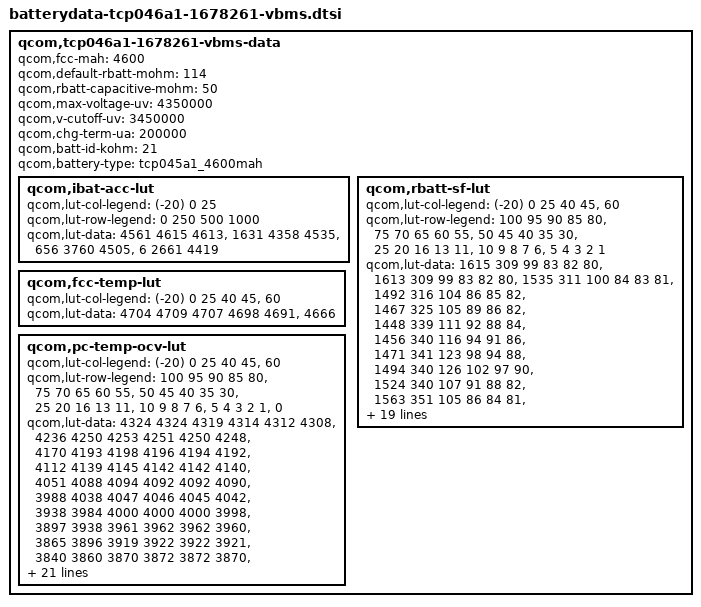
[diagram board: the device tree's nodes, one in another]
 qcom,tcp046a1-1678261-vbms-data {
	qcom,fcc-mah = <4600>;
	qcom,default-rbatt-mohm = <114>;
	qcom,rbatt-capacitive-mohm = <50>;
	qcom,max-voltage-uv = <4350000>;
	qcom,v-cutoff-uv = <3450000>;
	qcom,chg-term-ua = <200000>;
	qcom,batt-id-kohm = <21>;
	qcom,battery-type = "tcp045a1_4600mah";

	qcom,ibat-acc-lut {
		qcom,lut-col-legend = <(-20) 0 25>;
		qcom,lut-row-legend = <0 250 500 1000>;
		qcom,lut-data = <4561 4615 4613>,
				<1631 4358 4535>,
				<656 3760 4505>,
				<6 2661 4419>;
	};

	qcom,rbatt-sf-lut {
		qcom,lut-col-legend = <(-20) 0 25 40 45>,
				<60>;
		qcom,lut-row-legend = <100 95 90 85 80>,
				<75 70 65 60 55>,
				<50 45 40 35 30>,
				<25 20 16 13 11>,
				<10 9 8 7 6>,
				<5 4 3 2 1>;
		qcom,lut-data = <1615 309 99 83 82 80>,
				<1613 309 99 83 82 80>,
				<1535 311 100 84 83 81>,
				<1492 316 104 86 85 82>,
				<1467 325 105 89 86 82>,
				<1448 339 111 92 88 84>,
				<1456 340 116 94 91 86>,
				<1471 341 123 98 94 88>,
				<1494 340 126 102 97 90>,
				<1524 340 107 91 88 82>,
				<1563 351 105 86 84 81>,
				<1611 363 107 88 85 82>,
				<1659 385 111 90 88 84>,
				<1710 415 112 92 90 86>,
				<1765 447 114 93 89 84>,
				<1830 481 117 90 86 82>,
				<1911 514 118 90 87 82>,
				<1991 545 119 90 87 82>,
				<2147 573 118 91 88 82>,
				<2235 584 122 94 89 82>,
				<2382 601 126 95 90 83>,
				<2549 619 128 96 91 85>,
				<2735 636 132 98 92 85>,
				<2957 659 137 99 92 85>,
				<3255 680 139 96 91 84>,
				<3601 700 135 96 91 85>,
				<4049 725 137 98 93 87>,
				<4759 754 144 102 97 91>,
				<5844 804 160 114 109 98>,
				<8682 956 222 149 128 120>;
	};

	qcom,fcc-temp-lut {
		qcom,lut-col-legend = <(-20) 0 25 40 45>,
				<60>;
		qcom,lut-data = <4704 4709 4707 4698 4691>,
				<4666>;
	};

	qcom,pc-temp-ocv-lut {
		qcom,lut-col-legend = <(-20) 0 25 40 45>,
				<60>;
		qcom,lut-row-legend = <100 95 90 85 80>,
				<75 70 65 60 55>,
				<50 45 40 35 30>,
				<25 20 16 13 11>,
				<10 9 8 7 6>,
				<5 4 3 2 1>,
				<0>;
		qcom,lut-data = <4324 4324 4319 4314 4312 4308>,
				<4236 4250 4253 4251 4250 4248>,
				<4170 4193 4198 4196 4194 4192>,
				<4112 4139 4145 4142 4142 4140>,
				<4051 4088 4094 4092 4092 4090>,
				<3988 4038 4047 4046 4045 4042>,
				<3938 3984 4000 4000 4000 3998>,
				<3897 3938 3961 3962 3962 3960>,
				<3865 3896 3919 3922 3922 3921>,
				<3840 3860 3870 3872 3872 3870>,
				<3818 3832 3840 3840 3840 3840>,
				<3800 3810 3817 3817 3817 3817>,
				<3784 3793 3798 3799 3798 3798>,
				<3766 3780 3782 3782 3782 3781>,
				<3748 3764 3770 3766 3766 3762>,
				<3726 3748 3756 3748 3745 3735>,
				<3702 3728 3732 3724 3721 3711>,
				<3676 3708 3702 3693 3690 3682>,
				<3654 3694 3685 3677 3674 3666>,
				<3638 3684 3682 3675 3672 3664>,
				<3628 3678 3681 3674 3671 3662>,
				<3614 3672 3679 3672 3669 3660>,
				<3600 3664 3676 3670 3666 3658>,
				<3582 3653 3670 3664 3661 3650>,
				<3561 3637 3656 3647 3642 3628>,
				<3534 3612 3620 3610 3604 3590>,
				<3501 3574 3570 3557 3554 3540>,
				<3455 3518 3504 3492 3490 3476>,
				<3388 3438 3418 3407 3408 3392>,
				<3270 3311 3286 3279 3286 3262>,
				<3000 3000 3000 3000 3000 3000>;
	};
};
